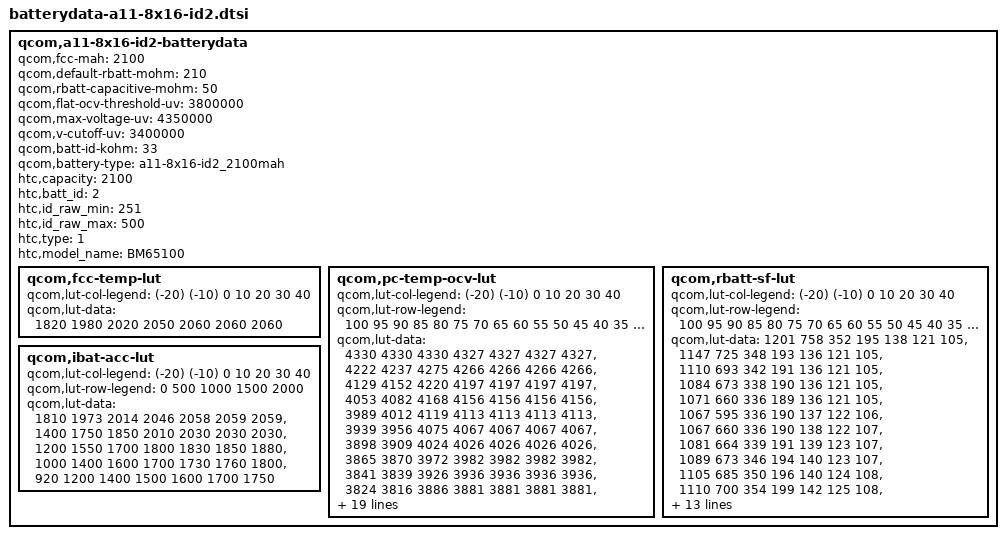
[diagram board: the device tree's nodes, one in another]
/* Copyright (c) 2013, The Linux Foundation. All rights reserved.
 *
 * This program is free software; you can redistribute it and/or modify
 * it under the terms of the GNU General Public License version 2 and
 * only version 2 as published by the Free Software Foundation.
 *
 * This program is distributed in the hope that it will be useful,
 * but WITHOUT ANY WARRANTY; without even the implied warranty of
 * MERCHANTABILITY or FITNESS FOR A PARTICULAR PURPOSE.  See the
 * GNU General Public License for more details.
 */

qcom,a11-8x16-id2-batterydata {
	qcom,fcc-mah = <2100>;
	qcom,default-rbatt-mohm = <210>;
	qcom,rbatt-capacitive-mohm = <50>;
	qcom,flat-ocv-threshold-uv = <3800000>;
	qcom,max-voltage-uv = <4350000>;
	qcom,v-cutoff-uv = <3400000>;
	qcom,batt-id-kohm = <33>;
	qcom,battery-type = "a11-8x16-id2_2100mah";
	htc,capacity = <2100>;
	htc,batt_id = <2>;
	htc,id_raw_min = <251>;
	htc,id_raw_max = <500>;
	htc,type = <1>;
	htc,model_name = "BM65100";

	qcom,fcc-temp-lut {
		qcom,lut-col-legend = <(-20) (-10) 0 10 20 30 40>;
		qcom,lut-data = <1820 1980 2020 2050 2060 2060 2060>;
	};

	qcom,pc-temp-ocv-lut {
		qcom,lut-col-legend = <(-20) (-10) 0 10 20 30 40>;
		qcom,lut-row-legend = <100 95 90 85 80 75 70 65 60 55 50 45 40 35 30 25 20 15 10 9 8 7 6 5 4 3 2 1 0>;
		qcom,lut-data = <4330 4330 4330 4327 4327 4327 4327>,
				<4222 4237 4275 4266 4266 4266 4266>,
				<4129 4152 4220 4197 4197 4197 4197>,
				<4053 4082 4168 4156 4156 4156 4156>,
				<3989 4012 4119 4113 4113 4113 4113>,
				<3939 3956 4075 4067 4067 4067 4067>,
				<3898 3909 4024 4026 4026 4026 4026>,
				<3865 3870 3972 3982 3982 3982 3982>,
				<3841 3839 3926 3936 3936 3936 3936>,
				<3824 3816 3886 3881 3881 3881 3881>,
				<3810 3804 3855 3865 3865 3865 3865>,
				<3796 3793 3831 3838 3838 3838 3838>,
				<3781 3783 3811 3828 3828 3828 3828>,
				<3766 3771 3795 3815 3815 3815 3815>,
				<3750 3757 3783 3810 3810 3810 3810>,
				<3735 3737 3767 3795 3795 3795 3795>,
				<3720 3716 3733 3785 3785 3785 3785>,
				<3700 3676 3701 3745 3745 3745 3745>,
				<3674 3625 3686 3706 3706 3706 3706>,
				<3670 3617 3673 3690 3690 3690 3690>,
				<3667 3608 3661 3676 3676 3676 3676>,
				<3659 3597 3631 3660 3660 3660 3660>,
				<3652 3585 3602 3650 3650 3650 3650>,
				<3643 3572 3560 3615 3615 3615 3615>,
				<3634 3558 3517 3580 3580 3580 3580>,
				<3622 3542 3462 3490 3490 3490 3490>,
				<3611 3525 3406 3420 3420 3420 3420>,
				<3598 3499 3309 3255 3255 3255 3255>,
				<3585 3472 3213 3081 3081 3081 3081>;
	};

	qcom,rbatt-sf-lut {
		qcom,lut-col-legend = <(-20) (-10) 0 10 20 30 40>;
		qcom,lut-row-legend = <100 95 90 85 80 75 70 65 60 55 50 45 40 35 30 25 20 15 10 8 6 4 2 0>;
		qcom,lut-data = <1201 758 352 195 138 121 105>,
						<1147 725 348 193 136 121 105>,
						<1110 693 342 191 136 121 105>,
						<1084 673 338 190 136 121 105>,
						<1071 660 336 189 136 121 105>,
						<1067 595 336 190 137 122 106>,
						<1067 660 336 190 138 122 107>,
						<1081 664 339 191 139 123 107>,
						<1089 673 346 194 140 123 107>,
						<1105 685 350 196 140 124 108>,
						<1110 700 354 199 142 125 108>,
						<1118 717 363 202 145 127 109>,
						<1129 728 372 208 148 129 111>,
						<1139 744 382 213 152 132 112>,
						<1145 755 397 220 157 135 114>,
						<1190 770 407 230 161 138 116>,
						<1222 805 420 242 168 142 118>,
						<1234 826 433 253 179 150 121>,
						<1245 831 440 263 217 180 144>,
						<1268 838 449 268 220 196 155>,
						<1270 852 458 310 230 200 175>,
						<1274 866 472 350 250 222 203>,
						<1293 871 488 370 270 240 231>,
						<1315 881 513 400 300 260 250>;
	};

	qcom,ibat-acc-lut {
		qcom,lut-col-legend = <(-20) (-10) 0 10 20 30 40>;
		qcom,lut-row-legend = <0 500 1000 1500 2000>;
		qcom,lut-data = <1810 1973 2014 2046 2058 2059 2059>,
						<1400 1750 1850 2010 2030 2030 2030>,
						<1200 1550 1700 1800 1830 1850 1880>,
						<1000 1400 1600 1700 1730 1760 1800>,
						<920 1200 1400 1500 1600 1700 1750>;
	};
};
